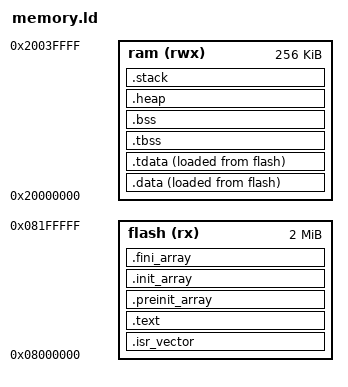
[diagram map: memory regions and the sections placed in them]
/*
 * memory.ld -- linker script template for variant cortex-m33-hard-fpv5-sp-d16 (arm-none-eabi).
 *
 * Generated by lib-build. Only the MEMORY block should normally need
 * editing: fill in the actual flash and RAM origin / length for your
 * chip. The SECTIONS block already provides every symbol picolibc's
 * crt0 expects (stack, data, bss, TLS, init_array, fini_array, heap).
 */

/* ==== EDIT ME: your chip's memory map =================================== */
MEMORY
{
    flash (rx) : ORIGIN = 0x08000000, LENGTH = 2048K
    ram  (rwx) : ORIGIN = 0x20000000, LENGTH = 256K
}

/* ==== Optional tuning =================================================== */
__stack_size = 8K;      /* reserved at the top of RAM for the MSP */
__heap_min   = 4K;      /* minimum bytes between _end and stack top */

ENTRY(Reset_Handler)

SECTIONS
{
    /* ---- Flash: vector table must be first so it lands at ORIGIN(flash) */
    .isr_vector : {
        KEEP(*(.isr_vector))
    } > flash

    .text : ALIGN(4) {
        *(.text .text.*)
        *(.init .fini)
        *(.glue_7 .glue_7t)
        *(.rodata .rodata.*)
        . = ALIGN(4);
        __text_end = .;
        PROVIDE(__etext = __text_end);
        PROVIDE(_etext  = __text_end);
        PROVIDE(etext   = __text_end);
    } > flash

    /* C++ static initialisation arrays. KEEP is mandatory -- without it
       gc-sections drops the pointers and global ctors never run. */
    .preinit_array : ALIGN(4) {
        PROVIDE_HIDDEN(__preinit_array_start = .);
        KEEP(*(.preinit_array))
        PROVIDE_HIDDEN(__preinit_array_end = .);
    } > flash

    .init_array : ALIGN(4) {
        PROVIDE_HIDDEN(__init_array_start = .);
        KEEP(*(SORT_BY_INIT_PRIORITY(.init_array.*)))
        KEEP(*(.init_array))
        PROVIDE_HIDDEN(__init_array_end = .);
    } > flash

    .fini_array : ALIGN(4) {
        PROVIDE_HIDDEN(__fini_array_start = .);
        KEEP(*(SORT_BY_INIT_PRIORITY(.fini_array.*)))
        KEEP(*(.fini_array))
        PROVIDE_HIDDEN(__fini_array_end = .);
    } > flash

    /* ---- RAM: .data has its initial image stored in flash (LMA) -------- */
    .data : ALIGN(4) {
        __data_start = .;
        *(.data .data.*)
        . = ALIGN(4);
        __data_end = .;
    } > ram AT > flash
    __data_source = LOADADDR(.data);
    __data_size   = __data_end - __data_start;

    /* ---- Thread-local storage (picolibc uses __thread errno!) ---------- */
    .tdata : ALIGN(4) {
        __tls_base    = .;
        __tdata_start = .;
        *(.tdata .tdata.*)
        __tdata_end   = .;
    } > ram AT > flash
    __tdata_source = LOADADDR(.tdata);
    __tdata_size   = __tdata_end - __tdata_start;

    .tbss (NOLOAD) : ALIGN(4) {
        __tbss_start = .;
        *(.tbss .tbss.*)
        *(.tcommon)
        __tbss_end = .;
    } > ram
    __tbss_size = __tbss_end - __tbss_start;
    __tls_size  = __tbss_end - __tls_base;
    __arm32_tls_tcb_offset = 8;

    /* ---- BSS ----------------------------------------------------------- */
    .bss (NOLOAD) : ALIGN(4) {
        __bss_start = .;
        *(.bss .bss.*)
        *(COMMON)
        . = ALIGN(4);
        __bss_end = .;
    } > ram
    __bss_size = __bss_end - __bss_start;

    /* ---- Heap grows up from _end; stack grows down from RAM top -------- */
    .heap (NOLOAD) : ALIGN(8) {
        _end = .;
        PROVIDE(end = .);
        __heap_start = .;
        . = . + __heap_min;           /* ensure some minimum */
    } > ram
    __heap_end = ORIGIN(ram) + LENGTH(ram) - __stack_size;

    .stack (NOLOAD) : ALIGN(8) {
        . = ORIGIN(ram) + LENGTH(ram) - __stack_size;
        __stack_limit = .;
        . = . + __stack_size;
    } > ram
    __stack = ORIGIN(ram) + LENGTH(ram);

    /* ---- Toss things we don't need on baremetal ------------------------ */
    /DISCARD/ : {
        *(.ARM.exidx .ARM.exidx.*)    /* exceptions are disabled */
        *(.ARM.extab .ARM.extab.*)
        *(.eh_frame  .eh_frame.*)
    }

    /* ---- Sanity check -------------------------------------------------- */
    ASSERT(__heap_end >= __heap_start + __heap_min,
           "ERROR: RAM exhausted: heap would overlap stack. "
           "Shrink __stack_size or grow RAM.")
}
